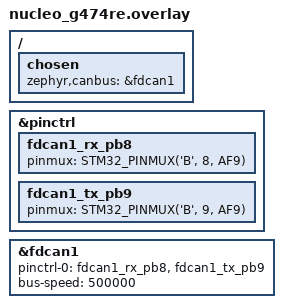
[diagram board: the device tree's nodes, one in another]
&pinctrl {
    fdcan1_rx_pb8: fdcan1_rx_pb8 {
        pinmux = <STM32_PINMUX('B', 8, AF9)>;
    };
    fdcan1_tx_pb9: fdcan1_tx_pb9 {
        pinmux = <STM32_PINMUX('B', 9, AF9)>;
    };
};

&fdcan1 {
    pinctrl-0 = <&fdcan1_rx_pb8 &fdcan1_tx_pb9>;
    pinctrl-names = "default";
    status = "okay";
    bus-speed = <500000>;
};

/ {
    chosen {
        zephyr,canbus = &fdcan1;
    };
};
